AUTOSAR XML (schema 00048)
standard types defined: Boolean, SInt8, SInt16, SInt32, UInt8, UInt16, UInt32, UInt64, Float32, Float64, boolean, uint8, uint16, uint32, uint64, sint8, sint16, sint32, sint64, float32, float64, Std_ReturnType, sint8_least, sint16_least, uint16_least, uint32_least, uint8_least, sint32_least, void
package /AUTOSAR/StdTypes/DataConstrs
  range SInt8_Constr: raw -128..127
  range SInt16_Constr: raw -32768..32767
  range SInt32_Constr: raw -2147483648..2147483647
  range UInt16_ConStr: raw 0..65535
  range UInt64_Constr: raw 0..18446744073709551615
  range Boolean_Constr: phys 0..1
package /AUTOSAR/DataTypes
  13 x impl type, all with category=VALUE, type-emitter=Platform_Type:
    Std_VersionInfoType
    Std_Std_TransformerError
    PduIdType
    PduInfoType
    PduLengthType
    PNCHandleType
    TPParameterType
    BufReq_ReturnType
    TpDataStateType
    RetryInfoType
    NetworkHandleType
    lcomConfigldType
    lcomSwitch_ErrorType
package /AUTOSAR/ServiceComponents/GeneratedComM
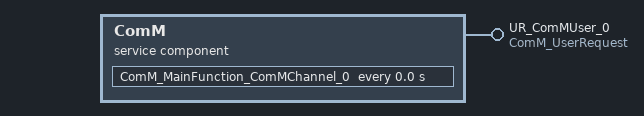
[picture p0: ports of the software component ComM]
  service sw component type ComM: category=SERVICE_COMPONENT
    provide port UR_ComMUser_0: provided-interface=ComM_UserRequest
    behavior ComMBehavior: handle-termination-and-restart=NO-SUPPORT, port-api-option{enable-take-address=true, indirect-api=false, port-defined-argument-value{value=User:0, value-type=ComM_UserHandleType}, port=UR_ComMUser_0}
      5 x operation invoked event:
        UR_ComMUser_0_GetCurrentComMode_oie: start-on-event=GetCurrentComMode, operation=UR_ComMUser_0.GetCurrentComMode
        UR_ComMUser_0_GetCurrentPNCComMode_oie: start-on-event=GetCurrentPNCComMode, operation=UR_ComMUser_0.GetCurrentPNCComMode
        UR_ComMUser_0_GetMaxComMode_oie: start-on-event=GetMaxComMode, operation=UR_ComMUser_0.GetMaxComMode
        UR_ComMUser_0_GetRequestedComMode_oie: start-on-event=GetRequestedComMode, operation=UR_ComMUser_0.GetRequestedComMode
        UR_ComMUser_0_RequestComMode_oie: start-on-event=RequestComMode, operation=UR_ComMUser_0.RequestComMode
      timing event ComM_MainFunction_ComMChannel_0_TimingEvent: start-on-event=ComM_MainFunction_ComMChannel_0, period=0.0
      6 x runnable, all with can-be-invoked-concurrently=true:
        GetCurrentComMode: symbol=ComM_GetCurrentComMode
        GetCurrentPNCComMode: symbol=ComM_GetCurrentPNCComMode
        GetMaxComMode: symbol=ComM_GetMaxComMode
        GetRequestedComMode: symbol=ComM_GetRequestedComMode
        RequestComMode: symbol=ComM_RequestComMode
        ComM_MainFunction_ComMChannel_0
  swc implementation ComMImplementation: programming-language=C, sw-version=2.1.0, vendor-id=62, behavior=ComMBehavior
package /AUTOSAR/ServiceComponents/GeneratedComM/Interfaces
  client server interface ComM_UserRequest: is-service=true, service-kind=COM-MANAGER
    5 x operation:
      GetCurrentComMode: possible-error=[ComM_UserRequest/E_OK, ComM_UserRequest/E_NOT_OK]
        arg ComMode: type=ComM_ModeType, direction=OUT, server-argument-impl-policy=USE-ARGUMENT-TYPE
      GetCurrentPNCComMode: possible-error=[ComM_UserRequest/E_OK, ComM_UserRequest/E_NOT_OK, E_MULTIPLE_PNC_ASSIGNED, E_NO_PNC_ASSIGNED]
        arg ComMode: type=ComM_ModeType, direction=OUT, server-argument-impl-policy=USE-ARGUMENT-TYPE
      GetMaxComMode: possible-error=[ComM_UserRequest/E_OK, ComM_UserRequest/E_NOT_OK]
        arg ComMode: type=ComM_ModeType, direction=OUT, server-argument-impl-policy=USE-ARGUMENT-TYPE
      GetRequestedComMode: possible-error=[ComM_UserRequest/E_OK, ComM_UserRequest/E_NOT_OK]
        arg ComMode: type=ComM_ModeType, direction=OUT, server-argument-impl-policy=USE-ARGUMENT-TYPE
      RequestComMode: possible-error=[ComM_UserRequest/E_OK, ComM_UserRequest/E_NOT_OK, E_MODE_LIMITATION]
        arg ComMode: type=ComM_ModeType, direction=IN, server-argument-impl-policy=USE-ARGUMENT-TYPE
    5 x error:
      E_OK: error-code=0
      E_NOT_OK: error-code=1
      E_MODE_LIMITATION: error-code=2
      E_MULTIPLE_PNC_ASSIGNED: error-code=3
      E_NO_PNC_ASSIGNED: error-code=4
package /AUTOSAR/ServiceComponents/GeneratedComM/DataTypes
  4 x impl type, all with category=VALUE, base-type=uint8, range raw 0..255:
    ComM_ModeType: compu {0=COMM_NO_COMMUNICATION, 1=COMM_SILENT_COMMUNICATION, 2=COMM_FULL_COMMUNICATION, 3=COMM_FULL_COMMUNICATION_WITH_WAKEUP_REQUEST}
    ComM_InhibitionStatusType: compu {mask 1: 1=COMM_WAKEUP_INHIBITION_ACTIVE_YES, mask 1: 0=COMM_WAKEUP_INHIBITION_ACTIVE_NO, mask 2: 2=COMM_LIMITED_TO_NO_COM_YES, mask 2: 0=COMM_LIMITED_TO_NO_COM_NO}
    ComM_UserHandleType
    NetWorkHandleType
package /AUTOSAR/ServiceComponents/GeneratedEcuM
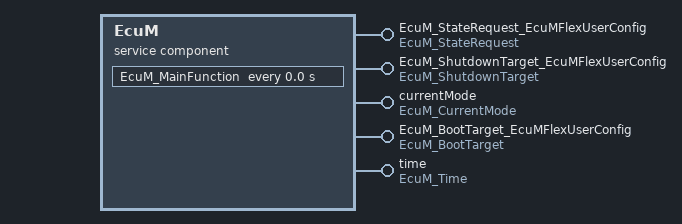
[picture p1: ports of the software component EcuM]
  service sw component type EcuM: category=SERVICE_COMPONENT
    5 x provide port:
      EcuM_StateRequest_EcuMFlexUserConfig: provided-interface=EcuM_StateRequest
      EcuM_ShutdownTarget_EcuMFlexUserConfig: provided-interface=EcuM_ShutdownTarget
      currentMode: mode-switch-sender-com-spec{mode-group=currentMode, mode-switched-ack=timeout=0.0, queue-length=1}, provided-interface=EcuM_CurrentMode
      EcuM_BootTarget_EcuMFlexUserConfig: provided-interface=EcuM_BootTarget
      time: provided-interface=EcuM_Time
    behavior EcuMBehavior: data-type-mapping=EcuMDataTypeMappingSet, handle-termination-and-restart=NO-SUPPORT
      9 x operation invoked event:
        EcuM_StateRequest_EcuMFlexUserConfig_ReleasePOSTRUN_oie: start-on-event=EcuM_StateRequest_ReleasePOSTRUN, operation=EcuM_StateRequest_EcuMFlexUserConfig.ReleasePOSTRUN
        EcuM_StateRequest_EcuMFlexUserConfig_ReleaseRUN_oie: start-on-event=EcuM_StateRequest_ReleaseRUN, operation=EcuM_StateRequest_EcuMFlexUserConfig.ReleaseRUN
        EcuM_StateRequest_EcuMFlexUserConfig_RequestPOSTRUN_oie: start-on-event=EcuM_StateRequest_RequestPOSTRUN, operation=EcuM_StateRequest_EcuMFlexUserConfig.RequestPOSTRUN
        EcuM_StateRequest_EcuMFlexUserConfig_RequestRUN_oie: start-on-event=EcuM_StateRequest_RequestRUN, operation=EcuM_StateRequest_EcuMFlexUserConfig.RequestRUN
        EcuM_ShutdownTarget_EcuMFlexUserConfig_GetLastShutdownTarget_oie: start-on-event=EcuM_ShutdownTarget_GetLastShutdownTarget, operation=EcuM_ShutdownTarget_EcuMFlexUserConfig.GetLastShutdownTarget
        EcuM_ShutdownTarget_EcuMFlexUserConfig_GetShutdownCause_oie: start-on-event=EcuM_ShutdownTarget_GetShutdownCause, operation=EcuM_ShutdownTarget_EcuMFlexUserConfig.GetShutdownCause
        EcuM_ShutdownTarget_EcuMFlexUserConfig_GetShutdownTarget_oie: start-on-event=EcuM_ShutdownTarget_GetShutdownTarget, operation=EcuM_ShutdownTarget_EcuMFlexUserConfig.GetShutdownTarget
        EcuM_ShutdownTarget_EcuMFlexUserConfig_SelectShutdownCause_oie: start-on-event=EcuM_ShutdownTarget_SelectShutdownCause, operation=EcuM_ShutdownTarget_EcuMFlexUserConfig.SelectShutdownCause
        EcuM_ShutdownTarget_EcuMFlexUserConfig_SelectShutdownTarget_oie: start-on-event=EcuM_ShutdownTarget_SelectShutdownTarget, operation=EcuM_ShutdownTarget_EcuMFlexUserConfig.SelectShutdownTarget
      timing event EcuM_MainFunction_TimingEvent: start-on-event=EcuM_MainFunction, period=0.0
      4 x operation invoked event:
        EcuM_BootTarget_EcuMFlexUserConfig_GetBootTarget_oie: start-on-event=EcuM_BootTarget_GetBootTarget, operation=EcuM_BootTarget_EcuMFlexUserConfig.GetBootTarget
        EcuM_BootTarget_EcuMFlexUserConfig_SelectBootTarget_oie: start-on-event=EcuM_BootTarget_SelectBootTarget, operation=EcuM_BootTarget_EcuMFlexUserConfig.SelectBootTarget
        time_GetCurrentTime_oie: start-on-event=EcuM_Time_GetCurrentTime, operation=time.GetCurrentTime
        time_GetWakeupTime_oie: start-on-event=EcuM_Time_GetWakeupTime, operation=time.GetWakeupTime
      port-api-options:
        {enable-take-address=true, indirect-api=false, port-defined-argument-value{value=User:0, value-type=EcuM_UserType}, port=EcuM_StateRequest_EcuMFlexUserConfig}
        enable-take-address=true, indirect-api=false, port=EcuM_ShutdownTarget_EcuMFlexUserConfig
        enable-take-address=true, indirect-api=false, port=currentMode
        enable-take-address=true, indirect-api=false, port=EcuM_BootTarget_EcuMFlexUserConfig
        enable-take-address=true, indirect-api=false, port=time
      14 x runnable:
        EcuM_StateRequest_ReleasePOSTRUN: can-be-invoked-concurrently=true, symbol=EcuM_ReleasePOST_RUN
        EcuM_StateRequest_ReleaseRUN: can-be-invoked-concurrently=true, symbol=EcuM_ReleaseRUN
        EcuM_StateRequest_RequestPOSTRUN: can-be-invoked-concurrently=true, symbol=EcuM_RequestPOST_RUN
        EcuM_StateRequest_RequestRUN: can-be-invoked-concurrently=true, symbol=EcuM_RequestRUN
        EcuM_ShutdownTarget_GetLastShutdownTarget: can-be-invoked-concurrently=true, symbol=EcuM_GetLastShutdownTarget
        EcuM_ShutdownTarget_GetShutdownCause: can-be-invoked-concurrently=true, symbol=EcuM_GetShutdownCause
        EcuM_ShutdownTarget_GetShutdownTarget: can-be-invoked-concurrently=true, symbol=EcuM_GetShutdownTarget
        EcuM_ShutdownTarget_SelectShutdownCause: can-be-invoked-concurrently=true, symbol=EcuM_SelectShutdownCause
        EcuM_ShutdownTarget_SelectShutdownTarget: can-be-invoked-concurrently=true, symbol=EcuM_SelectShutdownTarget
        EcuM_MainFunction
          mode switch point EcuM_MainFunction_EcuM_CurrentMode_ModeSwitchPoint: mode-group=currentMode.currentMode
        EcuM_BootTarget_GetBootTarget: can-be-invoked-concurrently=true, symbol=EcuM_GetBootTarget
        EcuM_BootTarget_SelectBootTarget: can-be-invoked-concurrently=true, symbol=EcuM_SelectBootTarget
        EcuM_Time_GetCurrentTime: can-be-invoked-concurrently=true, symbol=EcuM_GetCurrentTime
        EcuM_Time_GetWakeupTime: can-be-invoked-concurrently=true, symbol=EcuM_GetWakeupTime
  swc implementation EcuMImplementation: programming-language=C, sw-version=2.1.0, vendor-id=62, behavior=EcuMBehavior
  impl type EcuM_UserType: category=VALUE, base-type=uint8, range phys 0..31
package /AUTOSAR/ServiceComponents/GeneratedEcuM/ModeDeclarationGroups
  data type mapping set EcuMDataTypeMappingSet: mode-request-type-map{implementation-data-type=UInt8, mode-group=EcuM_Mode}
  mode declaration group EcuM_Mode: category=EXPLICIT_ORDER, initial-mode=STARTUP, on-transition-value=5
    5 x mode:
      STARTUP: value=0
      RUN: value=1
      POST_RUN: value=2
      SLEEP: value=3
      SHUTDOWN: value=4
package /AUTOSAR/ServiceComponents/GeneratedEcuM/Interfaces
  client server interface EcuM_StateRequest: is-service=true, service-kind=ECU-MANAGER
    4 x operation, all with possible-error=[EcuM_StateRequest/E_NOT_OK, EcuM_StateRequest/E_OK]:
      ReleasePOSTRUN
      ReleaseRUN
      RequestPOSTRUN
      RequestRUN
    error E_OK: error-code=0
    error E_NOT_OK: error-code=1
  client server interface EcuM_ShutdownTarget: is-service=true, service-kind=ECU-MANAGER
    5 x operation, all with possible-error=[EcuM_ShutdownTarget/E_NOT_OK, EcuM_ShutdownTarget/E_OK]:
      GetLastShutdownTarget
        arg shutdownTarget: type=EcuM_ShutdownTargetType, direction=OUT
        arg shutdownMode: type=EcuM_ShutdownModeType, direction=OUT
      GetShutdownCause
        arg shutdownCause: type=EcuM_ShutdownCauseType, direction=OUT
      GetShutdownTarget
        arg shutdownTarget: type=EcuM_ShutdownTargetType, direction=OUT
        arg shutdownMode: type=EcuM_ShutdownModeType, direction=OUT
      SelectShutdownCause
        arg shutdownCause: type=EcuM_ShutdownCauseType, direction=IN
      SelectShutdownTarget
        arg shutdownTarget: type=EcuM_ShutdownTargetType, direction=IN
        arg shutdownMode: type=EcuM_ShutdownModeType, direction=IN
    error E_OK: error-code=0
    error E_NOT_OK: error-code=1
  mode switch interface EcuM_CurrentMode: is-service=true, service-kind=ECU-MANAGER
    mode group currentMode: type=EcuM_Mode
  client server interface EcuM_BootTarget: is-service=true
    operation GetBootTarget: possible-error=EcuM_BootTarget/E_OK
      arg target: type=EcuM_BootTargetType, direction=OUT
    operation SelectBootTarget: possible-error=[EcuM_BootTarget/E_OK, EcuM_BootTarget/E_NOT_OK]
      arg target: type=EcuM_BootTargetType, direction=IN
    error E_OK: error-code=0
    error E_NOT_OK: error-code=1
  client server interface EcuM_Time: is-service=true, service-kind=ECU-MANAGER
    operation GetCurrentTime: possible-error=[EcuM_Time/E_NOT_OK, EcuM_Time/E_OK]
      arg time: type=EcuM_TimeType, direction=OUT
    operation GetWakeupTime: possible-error=[EcuM_Time/E_NOT_OK, EcuM_Time/E_OK]
      arg time: type=EcuM_TimeType, direction=OUT
    error E_OK: error-code=0
    error E_NOT_OK: error-code=1
package /AUTOSAR/ServiceComponents/GeneratedEcuM/DataTypes
  impl type EcuM_TimeType: category=VALUE, base-type=uint32, range raw 0..4294967295
  impl type EcuM_BootTargetType: category=VALUE, base-type=uint8, compu {0=ECUM_BOOT_TARGET_APP, 1=ECUM_BOOT_TARGET_OEM_BOOTLOADER, 2=ECUM_BOOT_TARGET_SYS_BOOTLOADER}, range phys 0..2
  impl type EcuM_ShutdownModeType: category=VALUE, base-type=uint16
  impl type EcuM_ShutdownTargetType: category=VALUE, base-type=uint8, compu {0x0=ECUM_SHUTDOWN_TARGET_SLEEP, 0x1=ECUM_SHUTDOWN_TARGET_RESET, 0x2=ECUM_SHUTDOWN_TARGET_OFF}
  impl type EcuM_ShutdownCauseType: category=VALUE, base-type=uint8, compu {0=ECUM_CAUSE_UNKNOWN, 1=ECUM_CAUSE_ECU_STATE, 2=ECUM_CAUSE_WDGM, 3=ECUM_CAUSE_DCM}, range phys 0..3
